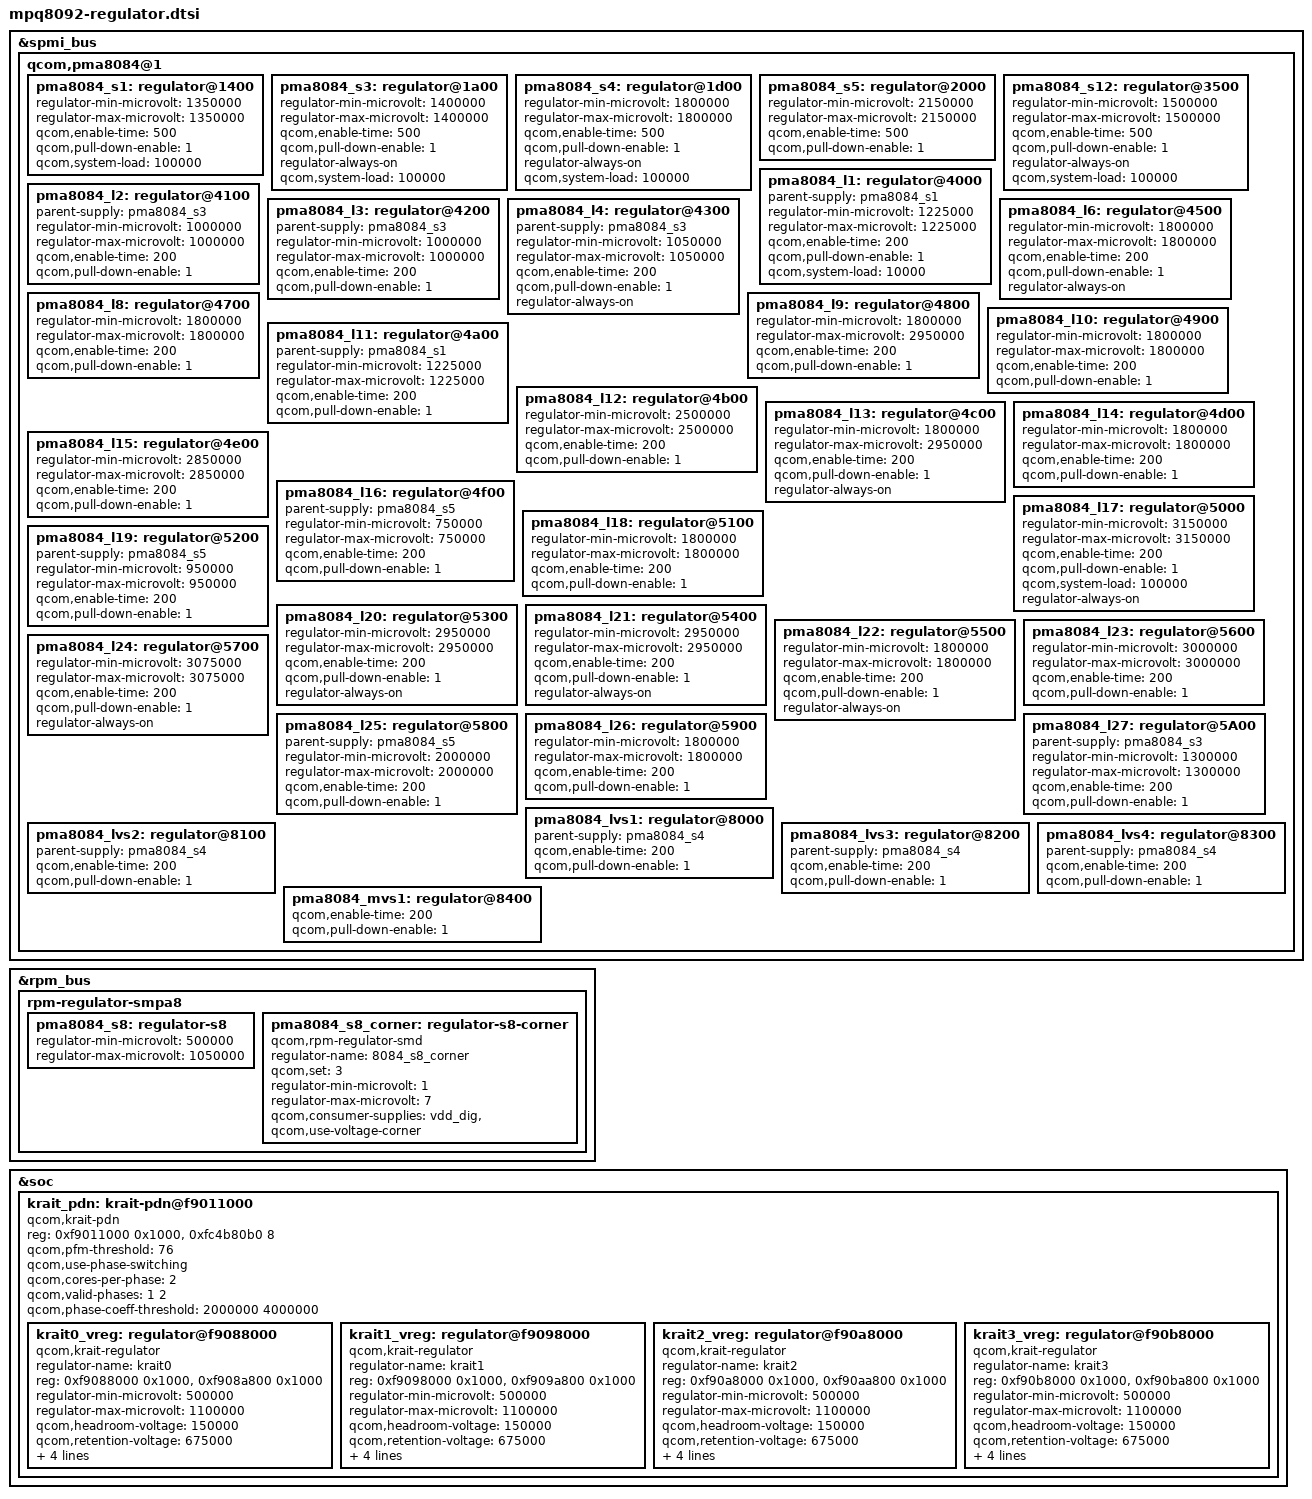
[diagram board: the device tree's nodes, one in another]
/* Copyright (c) 2012-2013, The Linux Foundation. All rights reserved.
 *
 * This program is free software; you can redistribute it and/or modify
 * it under the terms of the GNU General Public License version 2 and
 * only version 2 as published by the Free Software Foundation.
 *
 * This program is distributed in the hope that it will be useful,
 * but WITHOUT ANY WARRANTY; without even the implied warranty of
 * MERCHANTABILITY or FITNESS FOR A PARTICULAR PURPOSE.  See the
 * GNU General Public License for more details.
 */


/* QPNP controlled regulators: */

&spmi_bus {

	qcom,pma8084@1 {
		pma8084_s1: regulator@1400 {
			regulator-min-microvolt = <1350000>;
			regulator-max-microvolt = <1350000>;
			qcom,enable-time = <500>;
			qcom,pull-down-enable = <1>;
			qcom,system-load = <100000>;
			status = "okay";
		};

		pma8084_s3: regulator@1a00 {
			regulator-min-microvolt = <1400000>;
			regulator-max-microvolt = <1400000>;
			qcom,enable-time = <500>;
			qcom,pull-down-enable = <1>;
			regulator-always-on;
			qcom,system-load = <100000>;
			status = "okay";
		};

		pma8084_s4: regulator@1d00 {
			regulator-min-microvolt = <1800000>;
			regulator-max-microvolt = <1800000>;
			qcom,enable-time = <500>;
			qcom,pull-down-enable = <1>;
			regulator-always-on;
			qcom,system-load = <100000>;
			status = "okay";
		};

		pma8084_s5: regulator@2000 {
			regulator-min-microvolt = <2150000>;
			regulator-max-microvolt = <2150000>;
			qcom,enable-time = <500>;
			qcom,pull-down-enable = <1>;
			status = "okay";
		};

		pma8084_s12: regulator@3500 {
			regulator-min-microvolt = <1500000>;
			regulator-max-microvolt = <1500000>;
			qcom,enable-time = <500>;
			qcom,pull-down-enable = <1>;
			regulator-always-on;
			qcom,system-load = <100000>;
			status = "okay";
		};

		pma8084_l1: regulator@4000 {
			parent-supply = <&pma8084_s1>;
			regulator-min-microvolt = <1225000>;
			regulator-max-microvolt = <1225000>;
			qcom,enable-time = <200>;
			qcom,pull-down-enable = <1>;
			qcom,system-load = <10000>;
			status = "okay";
		};

		pma8084_l2: regulator@4100 {
			parent-supply = <&pma8084_s3>;
			regulator-min-microvolt = <1000000>;
			regulator-max-microvolt = <1000000>;
			qcom,enable-time = <200>;
			qcom,pull-down-enable = <1>;
			status = "okay";
		};

		pma8084_l3: regulator@4200 {
			parent-supply = <&pma8084_s3>;
			regulator-min-microvolt = <1000000>;
			regulator-max-microvolt = <1000000>;
			qcom,enable-time = <200>;
			qcom,pull-down-enable = <1>;
			status = "okay";
		};

		pma8084_l4: regulator@4300 {
			parent-supply = <&pma8084_s3>;
			regulator-min-microvolt = <1050000>;
			regulator-max-microvolt = <1050000>;
			qcom,enable-time = <200>;
			qcom,pull-down-enable = <1>;
			regulator-always-on;
			status = "okay";
		};

		pma8084_l6: regulator@4500 {
			regulator-min-microvolt = <1800000>;
			regulator-max-microvolt = <1800000>;
			qcom,enable-time = <200>;
			qcom,pull-down-enable = <1>;
			regulator-always-on;
			status = "okay";
		};

		pma8084_l8: regulator@4700 {
			regulator-min-microvolt = <1800000>;
			regulator-max-microvolt = <1800000>;
			qcom,enable-time = <200>;
			qcom,pull-down-enable = <1>;
			status = "okay";
		};

		pma8084_l9: regulator@4800 {
			regulator-min-microvolt = <1800000>;
			regulator-max-microvolt = <2950000>;
			qcom,enable-time = <200>;
			qcom,pull-down-enable = <1>;
			status = "okay";
		};

		pma8084_l10: regulator@4900 {
			regulator-min-microvolt = <1800000>;
			regulator-max-microvolt = <1800000>;
			qcom,enable-time = <200>;
			qcom,pull-down-enable = <1>;
			status = "okay";
		};

		pma8084_l11: regulator@4a00 {
			parent-supply = <&pma8084_s1>;
			regulator-min-microvolt = <1225000>;
			regulator-max-microvolt = <1225000>;
			qcom,enable-time = <200>;
			qcom,pull-down-enable = <1>;
			status = "okay";
		};

		pma8084_l12: regulator@4b00 {
			regulator-min-microvolt = <2500000>;
			regulator-max-microvolt = <2500000>;
			qcom,enable-time = <200>;
			qcom,pull-down-enable = <1>;
			status = "okay";
		};

		pma8084_l13: regulator@4c00 {
			regulator-min-microvolt = <1800000>;
			regulator-max-microvolt = <2950000>;
			qcom,enable-time = <200>;
			qcom,pull-down-enable = <1>;
			regulator-always-on;
			status = "okay";
		};

		pma8084_l14: regulator@4d00 {
			regulator-min-microvolt = <1800000>;
			regulator-max-microvolt = <1800000>;
			qcom,enable-time = <200>;
			qcom,pull-down-enable = <1>;
			status = "okay";
		};

		pma8084_l15: regulator@4e00 {
			regulator-min-microvolt = <2850000>;
			regulator-max-microvolt = <2850000>;
			qcom,enable-time = <200>;
			qcom,pull-down-enable = <1>;
			status = "okay";
		};

		pma8084_l16: regulator@4f00 {
			parent-supply = <&pma8084_s5>;
			regulator-min-microvolt = <750000>;
			regulator-max-microvolt = <750000>;
			qcom,enable-time = <200>;
			qcom,pull-down-enable = <1>;
			status = "okay";
		};

		pma8084_l17: regulator@5000 {
			regulator-min-microvolt = <3150000>;
			regulator-max-microvolt = <3150000>;
			qcom,enable-time = <200>;
			qcom,pull-down-enable = <1>;
			qcom,system-load = <100000>;
			regulator-always-on;
			status = "okay";
		};

		pma8084_l18: regulator@5100 {
			regulator-min-microvolt = <1800000>;
			regulator-max-microvolt = <1800000>;
			qcom,enable-time = <200>;
			qcom,pull-down-enable = <1>;
			status = "okay";
		};

		pma8084_l19: regulator@5200 {
			parent-supply = <&pma8084_s5>;
			regulator-min-microvolt = <950000>;
			regulator-max-microvolt = <950000>;
			qcom,enable-time = <200>;
			qcom,pull-down-enable = <1>;
			status = "okay";
		};

		pma8084_l20: regulator@5300 {
			regulator-min-microvolt = <2950000>;
			regulator-max-microvolt = <2950000>;
			qcom,enable-time = <200>;
			qcom,pull-down-enable = <1>;
			regulator-always-on;
			status = "okay";
		};

		pma8084_l21: regulator@5400 {
			regulator-min-microvolt = <2950000>;
			regulator-max-microvolt = <2950000>;
			qcom,enable-time = <200>;
			qcom,pull-down-enable = <1>;
			regulator-always-on;
			status = "okay";
		};

		pma8084_l22: regulator@5500 {
			regulator-min-microvolt = <1800000>;
			regulator-max-microvolt = <1800000>;
			qcom,enable-time = <200>;
			qcom,pull-down-enable = <1>;
			regulator-always-on;
			status = "okay";
		};

		pma8084_l23: regulator@5600 {
			regulator-min-microvolt = <3000000>;
			regulator-max-microvolt = <3000000>;
			qcom,enable-time = <200>;
			qcom,pull-down-enable = <1>;
			status = "okay";
		};

		pma8084_l24: regulator@5700 {
			regulator-min-microvolt = <3075000>;
			regulator-max-microvolt = <3075000>;
			qcom,enable-time = <200>;
			qcom,pull-down-enable = <1>;
			regulator-always-on;
			status = "okay";
		};

		pma8084_l25: regulator@5800 {
			parent-supply = <&pma8084_s5>;
			regulator-min-microvolt = <2000000>;
			regulator-max-microvolt = <2000000>;
			qcom,enable-time = <200>;
			qcom,pull-down-enable = <1>;
			status = "okay";
		};
		pma8084_l26: regulator@5900 {
			regulator-min-microvolt = <1800000>;
			regulator-max-microvolt = <1800000>;
			qcom,enable-time = <200>;
			qcom,pull-down-enable = <1>;
			status = "okay";
		};
		pma8084_l27: regulator@5A00 {
			parent-supply = <&pma8084_s3>;
			regulator-min-microvolt = <1300000>;
			regulator-max-microvolt = <1300000>;
			qcom,enable-time = <200>;
			qcom,pull-down-enable = <1>;
			status = "okay";
		};

		pma8084_lvs1: regulator@8000 {
			parent-supply = <&pma8084_s4>;
			qcom,enable-time = <200>;
			qcom,pull-down-enable = <1>;
			status = "okay";
		};

		pma8084_lvs2: regulator@8100 {
			parent-supply = <&pma8084_s4>;
			qcom,enable-time = <200>;
			qcom,pull-down-enable = <1>;
			status = "okay";
		};

		pma8084_lvs3: regulator@8200 {
			parent-supply = <&pma8084_s4>;
			qcom,enable-time = <200>;
			qcom,pull-down-enable = <1>;
			status = "okay";
		};

		pma8084_lvs4: regulator@8300 {
			parent-supply = <&pma8084_s4>;
			qcom,enable-time = <200>;
			qcom,pull-down-enable = <1>;
			status = "okay";
		};

		pma8084_mvs1: regulator@8400 {
			qcom,enable-time = <200>;
			qcom,pull-down-enable = <1>;
			status = "okay";
		};
	};
};

&rpm_bus {
	rpm-regulator-smpa8 {
		status = "okay";
		pma8084_s8: regulator-s8 {
			regulator-min-microvolt = <500000>;
			regulator-max-microvolt = <1050000>;
			status = "okay";
		};

		pma8084_s8_corner: regulator-s8-corner {
			compatible = "qcom,rpm-regulator-smd";
			regulator-name = "8084_s8_corner";
			qcom,set = <3>;
			regulator-min-microvolt = <1>;
			regulator-max-microvolt = <7>;
			qcom,consumer-supplies = "vdd_dig", "";
			qcom,use-voltage-corner;
		 };
	};
};

&soc {
	krait_pdn: krait-pdn@f9011000 {
		reg = <0xf9011000 0x1000>,
		      <0xfc4b80b0 8>;
		reg-names = "apcs_gcc", "phase-scaling-efuse";
		compatible = "qcom,krait-pdn";
		#address-cells = <1>;
		#size-cells = <1>;
		ranges;
		qcom,pfm-threshold = <76>;
		qcom,use-phase-switching;
		qcom,cores-per-phase = <2>;
		qcom,valid-phases = <1 2>;
		qcom,phase-coeff-threshold = <2000000 4000000>;

		krait0_vreg: regulator@f9088000 {
			compatible = "qcom,krait-regulator";
			regulator-name = "krait0";
			reg = <0xf9088000 0x1000>, /* APCS_ALIAS0_KPSS_ACS */
				<0xf908a800 0x1000>; /* APCS_ALIAS0_KPSS_MDD */
			reg-names = "acs", "mdd";
			regulator-min-microvolt = <500000>;
			regulator-max-microvolt = <1100000>;
			qcom,headroom-voltage = <150000>;
			qcom,retention-voltage = <675000>;
			qcom,ldo-default-voltage = <750000>;
			qcom,ldo-threshold-voltage = <850000>;
			qcom,ldo-delta-voltage = <25000>;
			qcom,cpu-num = <0>;
		};

		krait1_vreg: regulator@f9098000 {
			compatible = "qcom,krait-regulator";
			regulator-name = "krait1";
			reg = <0xf9098000 0x1000>, /* APCS_ALIAS1_KPSS_ACS */
				<0xf909a800 0x1000>; /* APCS_ALIAS1_KPSS_MDD */
			reg-names = "acs", "mdd";
			regulator-min-microvolt = <500000>;
			regulator-max-microvolt = <1100000>;
			qcom,headroom-voltage = <150000>;
			qcom,retention-voltage = <675000>;
			qcom,ldo-default-voltage = <750000>;
			qcom,ldo-threshold-voltage = <850000>;
			qcom,ldo-delta-voltage = <25000>;
			qcom,cpu-num = <1>;
		};

		krait2_vreg: regulator@f90a8000 {
			compatible = "qcom,krait-regulator";
			regulator-name = "krait2";
			reg = <0xf90a8000 0x1000>, /* APCS_ALIAS2_KPSS_ACS */
				<0xf90aa800 0x1000>; /* APCS_ALIAS2_KPSS_MDD */
			reg-names = "acs", "mdd";
			regulator-min-microvolt = <500000>;
			regulator-max-microvolt = <1100000>;
			qcom,headroom-voltage = <150000>;
			qcom,retention-voltage = <675000>;
			qcom,ldo-default-voltage = <750000>;
			qcom,ldo-threshold-voltage = <850000>;
			qcom,ldo-delta-voltage = <25000>;
			qcom,cpu-num = <2>;
		};

		krait3_vreg: regulator@f90b8000 {
			compatible = "qcom,krait-regulator";
			regulator-name = "krait3";
			reg = <0xf90b8000 0x1000>, /* APCS_ALIAS3_KPSS_ACS */
				<0xf90ba800 0x1000>; /* APCS_ALIAS3_KPSS_MDD */
			reg-names = "acs", "mdd";
			regulator-min-microvolt = <500000>;
			regulator-max-microvolt = <1100000>;
			qcom,headroom-voltage = <150000>;
			qcom,retention-voltage = <675000>;
			qcom,ldo-default-voltage = <750000>;
			qcom,ldo-threshold-voltage = <850000>;
			qcom,ldo-delta-voltage = <25000>;
			qcom,cpu-num = <3>;
		};
	};
};
